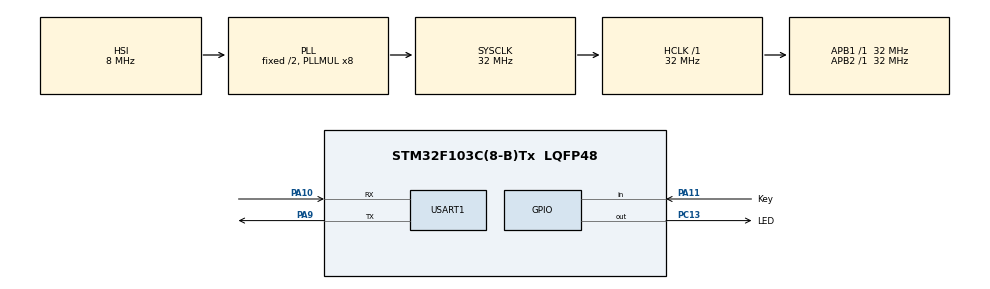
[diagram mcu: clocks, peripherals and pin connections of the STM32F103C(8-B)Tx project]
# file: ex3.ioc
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Mcu.Family=STM32F1
Mcu.Name=STM32F103C(8-B)Tx
Mcu.Package=LQFP48
NVIC.PriorityGroup=NVIC_PRIORITYGROUP_4
PA10.Mode=Asynchronous
PA10.Signal=USART1_RX
PA11.GPIO_Label=Key
PA11.GPIO_PuPd=GPIO_PULLUP
PA11.Signal=GPIO_Input
PA9.Mode=Asynchronous
PA9.Signal=USART1_TX
PC13-TAMPER-RTC.GPIO_Label=LED
PC13-TAMPER-RTC.GPIO_PuPd=GPIO_NOPULL
PC13-TAMPER-RTC.GPIO_Speed=GPIO_SPEED_FREQ_LOW
PC13-TAMPER-RTC.Signal=GPIO_Output
ProjectManager.HeapSize=0x200
ProjectManager.StackSize=0x400
ProjectManager.TargetToolchain=STM32CubeIDE
RCC.AHBFreq_Value=32000000
RCC.APB1Freq_Value=32000000
RCC.APB1TimFreq_Value=32000000
RCC.APB2Freq_Value=32000000
RCC.APB2TimFreq_Value=32000000
RCC.HCLKFreq_Value=32000000
RCC.PLLMUL=RCC_PLL_MUL8
RCC.SYSCLKFreq_VALUE=32000000
RCC.SYSCLKSource=RCC_SYSCLKSOURCE_PLLCLK
RCC.USBFreq_Value=32000000
TIM3.Period=10000-1
TIM3.Prescaler=32000-1
USART1.VirtualMode=VM_ASYNC
VP_SYS_VS_ND.Mode=No_Debug
VP_TIM3_VS_ClockSourceINT.Mode=Internal
board=custom

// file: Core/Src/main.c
/* USER CODE BEGIN Header */
/**
  ******************************************************************************
  * @file           : main.c
  * @brief          : Main program body
  ******************************************************************************
  * @attention
  *
  * <h2><center>&copy; Copyright (c) 2020 STMicroelectronics.
  * All rights reserved.</center></h2>
  *
  * This software component is licensed by ST under BSD 3-Clause license,
  * the "License"; You may not use this file except in compliance with the
  * License. You may obtain a copy of the License at:
  *                        opensource.org/licenses/BSD-3-Clause
  *
  ******************************************************************************
  */
/* USER CODE END Header */

#include "main.h"
#include "stdint-gcc.h"

/* USER CODE BEGIN PD */
#define KEY_DOWN 0
#define KEY_UP   1
#define KEY_UP_TO_DOWN 2
#define KEY_DOWN_TO_UP 3
#define LED_ON  0
#define LED_OFF 1
#define KEY_TIME_DIGIT 23
/* USER CODE END PD */

TIM_HandleTypeDef htim3;
UART_HandleTypeDef huart1;
const uint8_t USART_SendBuff_LEDON[] = "LED Current Status:ON";
const uint8_t USART_SendBuff_LEDOFF[] = "LED Current Status:OFF";
uint8_t USART_SendBuff_Key_Time[] = "Key Down Status Time:      ms";
uint8_t KeyFlag = KEY_UP;
uint16_t KeyDownTime;
//uint8_t USART_ReceiveBuff[10];

void SystemClock_Config(void);
static void MX_GPIO_Init(void);
static void MX_USART1_UART_Init(void);
static void MX_TIM3_Init(void);
uint8_t Key_Scan(void);

int main(void)
{
  /* USER CODE BEGIN 1 */
  //int8_t dconvert;
  /* USER CODE END 1 */

  /* MCU Configuration--------------------------------------------------------*/

  /* Reset of all peripherals, Initializes the Flash interface and the Systick. */
  HAL_Init();

  /* Configure the system clock */
  SystemClock_Config();

  /* Initialize all configured peripherals */
  MX_GPIO_Init();
  MX_USART1_UART_Init();
  MX_TIM3_Init();

  /* Infinite loop */
  while (1)
  {
    switch (Key_Scan())
    {
      case KEY_UP_TO_DOWN:
        __HAL_TIM_SET_COUNTER(&htim3, 0);
        HAL_GPIO_TogglePin(LED_GPIO_Port, LED_Pin);
        HAL_Delay(1);
        if (HAL_GPIO_ReadPin(LED_GPIO_Port, LED_Pin) == LED_ON)
          HAL_UART_Transmit(&huart1, (uint8_t *)USART_SendBuff_LEDON, sizeof(USART_SendBuff_LEDON), 0XFFFF);
        else
          HAL_UART_Transmit(&huart1, (uint8_t *)USART_SendBuff_LEDOFF, sizeof(USART_SendBuff_LEDOFF), 0XFFFF);
      break;

      case KEY_DOWN_TO_UP:
        KeyDownTime = __HAL_TIM_GET_COUNTER(&htim3);  /* 计数：从UP_TO_DOWN到DOWN_TO_UP的过程 */
        /* 对定时计数逐位转成ASCII码格式*/
        for (dconvert = 0; dconvert < 4; dconvert++)
        {
          USART_SendBuff_Key_Time[KEY_TIME_DIGIT+3-dconvert] = (uint8_t)(KeyDownTime % 10) + 48;
          KeyDownTime /= 10;
        }
        HAL_UART_Transmit(&huart1, (uint8_t *)USART_SendBuff_Key_Time, sizeof(USART_SendBuff_Key_Time), 0XFFFF);
      break;

      default:
      break;
    }
    // 接收原样发送
    // while(__HAL_UART_GET_FLAG(&huart1, UART_FLAG_RXNE) == RESET);
    // HAL_UART_Receive(&huart1, (uint8_t *)USART_ReceiveBuff, sizeof(USART_ReceiveBuff), 20);
    // HAL_UART_Transmit(&huart1, (uint8_t *)USART_ReceiveBuff, sizeof(USART_ReceiveBuff), 20);

  }
}

void SystemClock_Config(void)
{
  RCC_OscInitTypeDef RCC_OscInitStruct = {0};
  RCC_ClkInitTypeDef RCC_ClkInitStruct = {0};

  /** Initializes the CPU, AHB and APB busses clocks
  */
  RCC_OscInitStruct.OscillatorType = RCC_OSCILLATORTYPE_HSI;
  RCC_OscInitStruct.HSIState = RCC_HSI_ON;
  RCC_OscInitStruct.HSICalibrationValue = RCC_HSICALIBRATION_DEFAULT;
  RCC_OscInitStruct.PLL.PLLState = RCC_PLL_ON;
  RCC_OscInitStruct.PLL.PLLSource = RCC_PLLSOURCE_HSI_DIV2;
  RCC_OscInitStruct.PLL.PLLMUL = RCC_PLL_MUL8;
  if (HAL_RCC_OscConfig(&RCC_OscInitStruct) != HAL_OK)
  {
    Error_Handler();
  }
  /** Initializes the CPU, AHB and APB busses clocks
  */
  RCC_ClkInitStruct.ClockType = RCC_CLOCKTYPE_HCLK|RCC_CLOCKTYPE_SYSCLK
                              |RCC_CLOCKTYPE_PCLK1|RCC_CLOCKTYPE_PCLK2;
  RCC_ClkInitStruct.SYSCLKSource = RCC_SYSCLKSOURCE_PLLCLK;
  RCC_ClkInitStruct.AHBCLKDivider = RCC_SYSCLK_DIV1;
  RCC_ClkInitStruct.APB1CLKDivider = RCC_HCLK_DIV1;
  RCC_ClkInitStruct.APB2CLKDivider = RCC_HCLK_DIV1;

  if (HAL_RCC_ClockConfig(&RCC_ClkInitStruct, FLASH_LATENCY_1) != HAL_OK)
  {
    Error_Handler();
  }
}

static void MX_TIM3_Init(void)
{

  TIM_ClockConfigTypeDef sClockSourceConfig = {0};
  TIM_MasterConfigTypeDef sMasterConfig = {0};

  /* USER CODE BEGIN TIM3_Init 1 */
  __HAL_RCC_TIM3_CLK_ENABLE();    /* 使能TIM3时钟 */
  /* USER CODE END TIM3_Init 1 */
  htim3.Instance = TIM3;
  htim3.Init.Prescaler = 32000-1;
  htim3.Init.CounterMode = TIM_COUNTERMODE_UP;
  htim3.Init.Period = 10000-1;
  htim3.Init.ClockDivision = TIM_CLOCKDIVISION_DIV1;
  htim3.Init.AutoReloadPreload = TIM_AUTORELOAD_PRELOAD_DISABLE;
  if (HAL_TIM_Base_Init(&htim3) != HAL_OK)
  {
    Error_Handler();
  }
  sClockSourceConfig.ClockSource = TIM_CLOCKSOURCE_INTERNAL;
  if (HAL_TIM_ConfigClockSource(&htim3, &sClockSourceConfig) != HAL_OK)
  {
    Error_Handler();
  }
  sMasterConfig.MasterOutputTrigger = TIM_TRGO_RESET;
  sMasterConfig.MasterSlaveMode = TIM_MASTERSLAVEMODE_DISABLE;
  if (HAL_TIMEx_MasterConfigSynchronization(&htim3, &sMasterConfig) != HAL_OK)
  {
    Error_Handler();
  }
  /* USER CODE BEGIN TIM3_Init 2 */
  HAL_TIM_Base_Start(&htim3);     /* 开启TIM3 */
  /* USER CODE END TIM3_Init 2 */

}

static void MX_USART1_UART_Init(void)
{

  /* USER CODE BEGIN USART1_Init 0 */
  __HAL_RCC_USART1_CLK_ENABLE();
  /* USER CODE END USART1_Init 0 */

  huart1.Instance = USART1;
  huart1.Init.BaudRate = 115200;
  huart1.Init.WordLength = UART_WORDLENGTH_8B;
  huart1.Init.StopBits = UART_STOPBITS_1;
  huart1.Init.Parity = UART_PARITY_NONE;
  huart1.Init.Mode = UART_MODE_TX_RX;
  huart1.Init.HwFlowCtl = UART_HWCONTROL_NONE;
  huart1.Init.OverSampling = UART_OVERSAMPLING_16;
  if (HAL_UART_Init(&huart1) != HAL_OK)
  {
    Error_Handler();
  }

}

static void MX_GPIO_Init(void)
{
  GPIO_InitTypeDef GPIO_InitStruct = {0};

  /* GPIO Ports Clock Enable */
  __HAL_RCC_GPIOC_CLK_ENABLE();
  __HAL_RCC_GPIOA_CLK_ENABLE();

  /*Configure GPIO pin Output Level */
  HAL_GPIO_WritePin(LED_GPIO_Port, LED_Pin, GPIO_PIN_RESET);

  /*Configure GPIO pin : LED_Pin */
  GPIO_InitStruct.Pin = LED_Pin;
  GPIO_InitStruct.Mode = GPIO_MODE_OUTPUT_PP;
  GPIO_InitStruct.Pull = GPIO_NOPULL;
  GPIO_InitStruct.Speed = GPIO_SPEED_FREQ_LOW;
  HAL_GPIO_Init(LED_GPIO_Port, &GPIO_InitStruct);

  /*Configure GPIO pin : Key_Pin */
  GPIO_InitStruct.Pin = Key_Pin;
  GPIO_InitStruct.Mode = GPIO_MODE_INPUT;
  GPIO_InitStruct.Pull = GPIO_PULLUP;
  HAL_GPIO_Init(Key_GPIO_Port, &GPIO_InitStruct);

}

void Error_Handler(void)
{
}

/**
  * @brief   检测当前按键状态
  * @note    采用时延和重复检测的方法消除按键抖动带来的影响
  * @param   None
  * @retval  按键的状态
  *     @arg KEY_DOWN：按键按下
  *     @arg KEY_UP：按键弹起
  *     @arg KEY_UP_TO_DOWN：按键弹起到按下的跳变
  *     @arg KEY_DOWN_TO_UP：按键按下到弹起的跳变
  */
uint8_t Key_Scan(void)
{
  uint8_t KeyAssureNum;
  if (KeyFlag == KEY_UP && HAL_GPIO_ReadPin(Key_GPIO_Port, Key_Pin) == KEY_DOWN)
  {
    for (KeyAssureNum = 0; KeyAssureNum <= 10; KeyAssureNum++)
    {
      HAL_Delay(2);
      if (HAL_GPIO_ReadPin(Key_GPIO_Port, Key_Pin) != KEY_DOWN)
        return KEY_UP;
    }
    KeyFlag = KEY_DOWN;
    return KEY_UP_TO_DOWN;
  }
  else if (KeyFlag == KEY_DOWN && HAL_GPIO_ReadPin(Key_GPIO_Port, Key_Pin) == KEY_UP)
  {
    for (KeyAssureNum = 0; KeyAssureNum <= 10; KeyAssureNum++)
    {
      HAL_Delay(2);
      if (HAL_GPIO_ReadPin(Key_GPIO_Port, Key_Pin) != KEY_UP)
        return KEY_DOWN;
    }
    KeyFlag = KEY_UP;
    return KEY_DOWN_TO_UP;
  }
  return KeyFlag;
}

/************************ (C) COPYRIGHT STMicroelectronics *****END OF FILE****/
